# AT32F403A register map
Vendor: Keil; Series: AT32F403A; File version: 1.0
CPU: CM4 r0p1, little endian, no MPU, FPU, 4 interrupt priority bits
Registers are 32-bit, read-write, reset 0x0 unless marked. A register's access mark holds for its fields unless they carry their own. Offsets are from the block's base; [hi:lo] are bit positions.

## I2C1 — Inter integrated circuit
Base 0x40005400
Same registers: I2C2 0x40005800, I2C3 0x40015C00
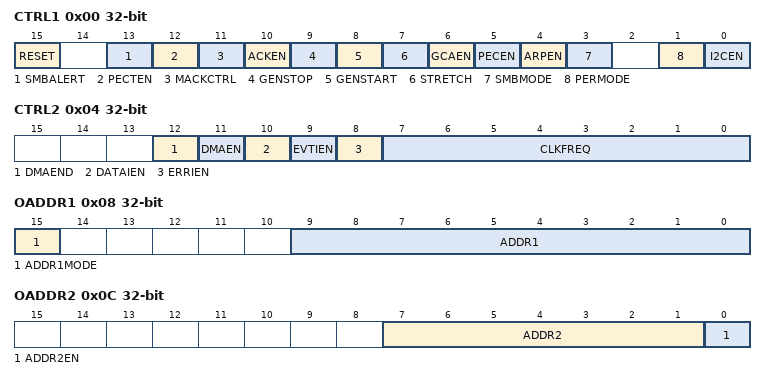
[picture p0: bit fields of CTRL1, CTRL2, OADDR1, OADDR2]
0x00 CTRL1 — Control register 1
  [15] RESET — I2C peripheral reset
    0=NotReset (I2C peripheral not under reset); 1=Reset (I2C peripheral under reset)
  [13] SMBALERT — SMBus alert pin set
    0=High (SMBus alert pin high); 1=Low (SMBus alert pin low)
  [12] PECTEN — Request PEC transmission enable
    on read: 0=Disabled (PEC transfer is disabled); 1=Enabled (PEC transfer is enabled) | on write: 0=Disable PEC transfer; 1=Enable PEC transfer
  [11] MACKCTRL — Master receiving mode acknowledge control
    0=Current (ACKEN bit controls ACK of the current byte being transferred); 1=Next (ACKEN bit controls ACK of the next byte to be transferred)
  [10] ACKEN — Acknowledge enable
    on read: 0=Disabled (No acknowledge returned); 1=Enabled (Acknowledge returned after a byte is received (matched address or data)) | on write: 0=Disable acknowledge; 1=Enable acknowledge
  [9] GENSTOP — Stop generation
    0=No Stop generation; 1=Stop (In master mode: repeated start generation, in slave mode: start generation when bus is free)
  [8] GENSTART — Start generation
    0=No Start generation; 1=Start (In master mode: stop generation after current byte/start, in slave mode: release SCL and SDA after current byte)
  [7] STRETCH — Clock stretching mode
    on read: 0=Disabled (Clock stretching mode is disabled); 1=Enabled (Clock stretching mode is enabled) | on write: 0=Disable clock stretching mode; 1=Enable clock stretching mode
  [6] GCAEN — General call address enable
    on read: 0=Disabled (General call address is disabled); 1=Enabled (General call address is enabled) | on write: 0=Disable general call address; 1=Enable general call address
  [5] PECEN — PEC calculation enable
    on read: 0=Disabled (PEC calculation is disabled); 1=Enabled (PEC calculation is enabled) | on write: 0=Disable PEC calculation; 1=Enable PEC calculation
  [4] ARPEN — SMBus address resolution protocol enable
    on read: 0=Disabled (SMBus address resolution protocol is disabled); 1=Enabled (SMBus address resolution protocol is enabled) | on write: 0=Disable SMBus address resolution protocol; 1=Enable SMBus address resolution protocol
  [3] SMBMODE — SMBus device mode
    0=Slave (SMBus slave); 1=Host (SMBus host)
  [1] PERMODE — I2C peripheral mode
    0=I2C (I2C mode); 1=SMBus mode
  [0] I2CEN — Peripheral enable
    on read: 0=Disabled (I2C peripheral is disabled); 1=Enabled (I2C peripheral is enabled) | on write: 0=Disable I2C peripheral; 1=Enable I2C peripheral
0x04 CTRL2 — Control register 2
  [12] DMAEND — DMA transfer end indication
    0=NotLast (Next DMA EOT is not the last transfer); 1=Last (Next DMA EOT is the last transfer)
  [11] DMAEN — DMA transfer enable
    on read: 0=Disabled (DMA transfer is disabled); 1=Enabled (DMA transfer is enabled) | on write: 0=Disable DMA transfer; 1=Enable DMA transfer
  [10] DATAIEN — Data transmission interrupt enable
    on read: 0=Disabled (Data transfer interrupt is disabled); 1=Enabled (Data transfer interrupt is enabled) | on write: 0=Disable Data transfer interrupt; 1=Enable Data transfer interrupt
  [9] EVTIEN — Event interrupt enable
    on read: 0=Disabled (Event interrupt is disabled); 1=Enabled (Event interrupt is enabled) | on write: 0=Disable Event interrupt; 1=Enable Event interrupt
  [8] ERRIEN — Error interrupt enable
    on read: 0=Disabled (Error interrupt is disabled); 1=Enabled (Error interrupt is enabled) | on write: 0=Disable Error interrupt; 1=Enable Error interrupt
  [7:0] CLKFREQ range 2..120 — Input clock frequency
0x08 OADDR1 — Own address register 1
  [15] ADDR1MODE — Address mode
    0=ADD7 (7-bit slave address); 1=ADD10 (10-bit slave address)
  [9:0] ADDR1 — Own address 1
0x0C OADDR2 — Own address register 2
  [7:1] ADDR2 — Own address 2
  [0] ADDR2EN — Own address 2 enable
    0=Single addressing mode; 1=Dual addressing mode
0x10 DT — Data register
  [7:0] DT — data register
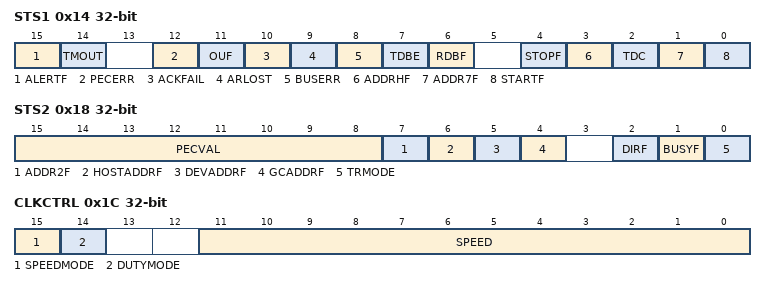
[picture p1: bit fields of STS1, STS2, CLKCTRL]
0x14 STS1 — Status register 1
  [15] ALERTF write-0-clears — SMBus alert
    on read: 0=NoAlert (No SMBALERT occured); 1=Alert (SMBALERT occurred) | on write: 0=Clear flag
  [14] TMOUT write-0-clears — Timeout error
    on read: 0=No Timeout error; 1=Timeout (SCL remained LOW for 25 ms) | on write: 0=Clear flag
  [12] PECERR write-0-clears — PEC receive error
    on read: 0=NoError (no PEC error: receiver returns ACK after PEC reception (if ACK=1)); 1=Error (PEC error: receiver returns NACK after PEC reception (whatever ACK)) | on write: 0=Clear flag
  [11] OUF write-0-clears — Overflow or underflow
    on read: 0=No overrun/underrun occured; 1=Overrun/underrun occured | on write: 0=Clear flag
  [10] ACKFAIL write-0-clears — Acknowledge failure
    on read: 0=NoFailure (No acknowledge failure); 1=Failure (Acknowledge failure) | on write: 0=Clear flag
  [9] ARLOST write-0-clears — Arbitration lost (master mode)
    on read: 0=NoLost (No Arbitration Lost detected); 1=Lost (Arbitration Lost detected) | on write: 0=Clear flag
  [8] BUSERR write-0-clears — Bus error
    on read: 0=NoError (No misplaced Start or Stop condition); 1=Error (Misplaced Start or Stop condition) | on write: 0=Clear flag
  [7] TDBE ro — Transmit data buffer empty (transmitters)
    0=NotEmpty (Data register not empty); 1=Empty (Data register empty)
  [6] RDBF ro — Receive data buffer full (receivers)
    0=Empty (Data register empty); 1=NotEmpty (Data register not empty)
  [4] STOPF ro — Stop detection (slave mode)
    0=No Stop condition detected; 1=Stop condition detected
  [3] ADDRHF ro — address header match (Master mode)
    0=NotMatch (Master 9~8 bit address head mismatch); 1=Match (Master 9~8 bit address head match)
  [2] TDC ro — Transmit data complete
    0=NotFinished (Data byte transfer not done); 1=Finished (Data byte transfer successful)
  [1] ADDR7F ro — Address sent (master mode)/matched (slave mode)
    0=NotMatch (Adress mismatched or not received); 1=Match (Received slave address matched with one of the enabled slave addresses)
  [0] STARTF ro — Start bit (Master mode)
    0=No Start condition; 1=Start condition generated
0x18 STS2 ro — Status register 2
  [15:8] PECVAL — PEC value
  [7] ADDR2F — Received address 2
    0=OADDR1 (Received address matches the contents of OADDR1); 1=OADDR2 (Received address matches the contents of OADDR2)
  [6] HOSTADDRF — SMBus host address receiving
    0=NotReceived (SMBus host address is not received); 1=Received (SMBus host address is received)
  [5] DEVADDRF — SMBus device address receiving
    0=NotReceived (SMBus device address is not received); 1=Received (SMBus device address is received)
  [4] GCADDRF — General call address reception
    0=NotReceived (General call address is not received); 1=Received (General call address is received)
  [2] DIRF — Transmission direction
    0=Reception (Data reception); 1=Transmission (Data transmission)
  [1] BUSYF — Bus busy
    0=Idle (Bus idle); 1=Busy (Bus busy)
  [0] TRMODE — Transmission mode
    0=Slave mode; 1=Master mode
0x1C CLKCTRL — Clock control register
  [15] SPEEDMODE — Speed mode selection
    0=Standard mode (up to 100 kHz); 1=Fast mode (up to 400 kHz)
  [14] DUTYMODE — Fast mode duty cycle
    0=Duty2_1 (The ratio of low to high is 2:1); 1=Duty16_9 (The ratio of low to high is 16:9)
  [11:0] SPEED — I2C bus speed config
0x20 TMRISE reset 0x2 — TRISE register
  [5:0] RISETIME — I2C bus rise time
